# RP2040 register map
Vendor: Raspberry Pi; Series: RP; File version: 0.1
CPU: CM0PLUS r0p1, little endian, MPU, no FPU, VTOR, 2 interrupt priority bits, 32 interrupts
Registers are 32-bit, read-write, reset 0x0 unless marked. A register's access mark holds for its fields unless they carry their own. Offsets are from the block's base; [hi:lo] are bit positions; {n}, {i} and the like mark numbered series; 'fields as' and 'values as' point back to an identical list.

## ADC — Control and data interface to SAR ADC
Base 0x4004C000
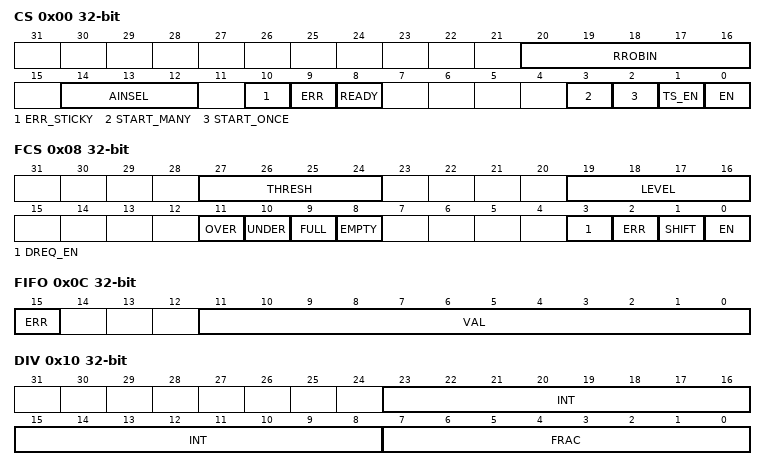
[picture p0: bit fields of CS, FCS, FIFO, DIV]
0x00 CS — ADC Control and Status
  [20:16] RROBIN — Round-robin sampling. 1 bit per channel. Set all bits to 0 to disable. Otherwise, the ADC will cycle through each enabled channel in a round-robin fashion. The first channel to be sampled will be the one currently indicated by AINSEL. AINSEL will be updated after each conversion with the newly-selected channel.
  [14:12] AINSEL — Select analog mux input. Updated automatically in round-robin mode.
  [10] ERR_STICKY write-1-clears — Some past ADC conversion encountered an error. Write 1 to clear.
  [9] ERR ro — The most recent ADC conversion encountered an error; result is undefined or noisy.
  [8] READY ro — 1 if the ADC is ready to start a new conversion. Implies any previous conversion has completed. 0 whilst conversion in progress.
  [3] START_MANY — Continuously perform conversions whilst this bit is 1. A new conversion will start immediately after the previous finishes.
  [2] START_ONCE write-1-clears — Start a single conversion. Self-clearing. Ignored if start_many is asserted.
  [1] TS_EN — Power on temperature sensor. 1 - enabled. 0 - disabled.
  [0] EN — Power on ADC and enable its clock. 1 - enabled. 0 - disabled.
0x04 RESULT — Result of most recent ADC conversion
  [11:0] RESULT ro
0x08 FCS — FIFO control and status
  [27:24] THRESH — DREQ/IRQ asserted when level >= threshold
  [19:16] LEVEL ro — The number of conversion results currently waiting in the FIFO
  [11] OVER write-1-clears — 1 if the FIFO has been overflowed. Write 1 to clear.
  [10] UNDER write-1-clears — 1 if the FIFO has been underflowed. Write 1 to clear.
  [9] FULL ro
  [8] EMPTY ro
  [3] DREQ_EN — If 1: assert DMA requests when FIFO contains data
  [2] ERR — If 1: conversion error bit appears in the FIFO alongside the result
  [1] SHIFT — If 1: FIFO results are right-shifted to be one byte in size. Enables DMA to byte buffers.
  [0] EN — If 1: write result to the FIFO after each conversion.
0x0C FIFO — Conversion result FIFO
  [15] ERR ro read-modifies — 1 if this particular sample experienced a conversion error. Remains in the same location if the sample is shifted.
  [11:0] VAL ro read-modifies
0x10 DIV — Clock divider. If non-zero, CS_START_MANY will start conversions at regular intervals rather than back-to-back. The divider is reset when either of these fields are written. Total period is 1 + INT + FRAC / 256
  [23:8] INT — Integer part of clock divisor.
  [7:0] FRAC — Fractional part of clock divisor. First-order delta-sigma.
0x14 INTR — Raw Interrupts
  [0] FIFO ro — Triggered when the sample FIFO reaches a certain level. This level can be programmed via the FCS_THRESH field.
0x18 INTE — Interrupt Enable
  [0] FIFO — Triggered when the sample FIFO reaches a certain level. This level can be programmed via the FCS_THRESH field.
0x1C INTF — Interrupt Force
  fields as INTE
0x20 INTS — Interrupt status after masking & forcing
  fields as INTR

## BUSCTRL — Register block for busfabric control signals and performance counters
Base 0x40030000
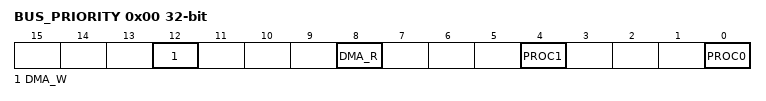
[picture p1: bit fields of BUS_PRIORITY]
0x00 BUS_PRIORITY — Set the priority of each master for bus arbitration.
  [12] DMA_W — 0 - low priority, 1 - high priority
  [8] DMA_R — 0 - low priority, 1 - high priority
  [4] PROC1 — 0 - low priority, 1 - high priority
  [0] PROC0 — 0 - low priority, 1 - high priority
0x04 BUS_PRIORITY_ACK — Bus priority acknowledge
  [0] BUS_PRIORITY_ACK ro — Goes to 1 once all arbiters have registered the new global priority levels. Arbiters update their local priority when servicing a new nonsequential access. In normal circumstances this will happen almost immediately.
{0x8+8i} PERFCTR{i} (i=0..3) — Bus fabric performance counter {i}
  [23:0] PERFCTR{i} write-1-clears — Busfabric saturating performance counter {i} Count some event signal from the busfabric arbiters. Write any value to clear. Select an event to count using PERFSEL{i}
{0xC+8i} PERFSEL{i} reset 0x1F (i=0..3) — Bus fabric performance event select for PERFCTR{i}
  [4:0] PERFSEL{i} — Select an event for PERFCTR{i}. Count either contested accesses, or all accesses, on a downstream port of the main crossbar.
    0=apb_contested; 1=apb; 2=fastperi_contested; 3=fastperi; 4=sram5_contested; 5=sram5; 6=sram4_contested; 7=sram4; 8=sram3_contested; 9=sram3; 10=sram2_contested; 11=sram2; 12=sram1_contested; 13=sram1; 14=sram0_contested; 15=sram0; 16=xip_main_contested; 17=xip_main; 18=rom_contested; 19=rom

## Notices in the file
Copyright (c) 2021 Raspberry Pi Ltd.
SPDX-License-Identifier: BSD-3-Clause
